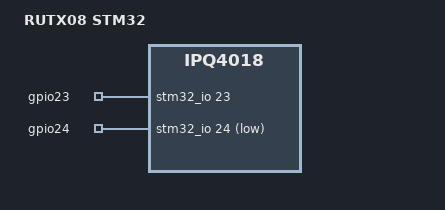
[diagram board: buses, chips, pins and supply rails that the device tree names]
#include "qcom-ipq4018-rutx-STM32.dtsi"

/ {
	model = "RUTX08 STM32";

	soc {
		gpio-export {
			compatible = "gpio-export";
			#size-cells = <0>;

			gpio_out_1 {
				gpio-export,name = "gpio23";
				gpio-export,output = <0>;
				gpio-export,direction_may_change;
				gpios = <&stm32_io 23 GPIO_ACTIVE_HIGH>;
			};

			gpio_in_1 {
				gpio-export,name = "gpio24";
				gpio-export,input = <0>;
				gpio-export,direction_may_change;
				gpios = <&stm32_io 24 GPIO_ACTIVE_LOW>;
			};
		};
	};
};
